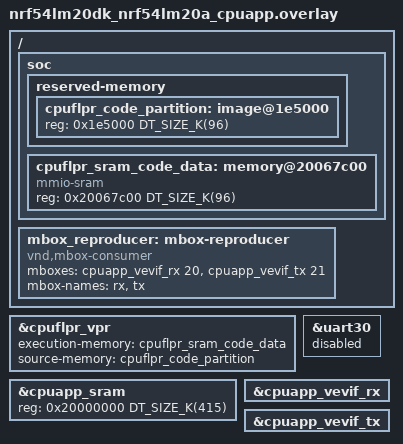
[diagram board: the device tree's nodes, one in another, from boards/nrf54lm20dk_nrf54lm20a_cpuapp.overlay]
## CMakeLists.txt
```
#
# Copyright (c) 2026 Nordic Semiconductor ASA
#
# SPDX-License-Identifier: LicenseRef-Nordic-5-Clause
#

cmake_minimum_required(VERSION 3.20.0)
find_package(Zephyr REQUIRED HINTS $ENV{ZEPHYR_BASE})
project(vevif_back_to_back)

target_sources(app PRIVATE src/main.c)
```

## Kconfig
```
#
# Copyright (c) 2026 Nordic Semiconductor ASA
#
# SPDX-License-Identifier: LicenseRef-Nordic-5-Clause
#

menu "VEVIF Back-To-Back Reproducer"

choice REPRO_MODE
	prompt "Back-to-back scenario"
	default REPRO_MODE_TASK_BURST

config REPRO_MODE_TASK_BURST
	bool "Host sends two back-to-back notifications"

config REPRO_MODE_REVERSE_BURST
	bool "Remote sends two back-to-back notifications after host kick"

endchoice

config REPRO_ITERATIONS
	int "Number of iterations"
	range 1 100000
	default 200

config REPRO_START_DELAY_MS
	int "Producer startup delay in milliseconds"
	range 0 60000
	default 2000

config REPRO_ITERATION_GAP_MS
	int "Delay between back-to-back pairs in milliseconds"
	range 0 1000
	default 1

config REPRO_OVERALL_TIMEOUT_MS
	int "Consumer timeout in milliseconds"
	range 1 60000
	default 10000

endmenu

source "Kconfig.zephyr"
```

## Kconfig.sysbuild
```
#
# Copyright (c) 2026 Nordic Semiconductor ASA
#
# SPDX-License-Identifier: LicenseRef-Nordic-5-Clause
#

source "share/sysbuild/Kconfig"

config REMOTE_BOARD
	string "Remote board"
	default "nrf54lm20dk/nrf54lm20a/cpuflpr" if "$(BOARD_TARGET_STRING)" = "NRF54LM20DK_NRF54LM20A_CPUAPP"
	default "nrf54lm20dk/nrf54lm20b/cpuflpr" if "$(BOARD_TARGET_STRING)" = "NRF54LM20DK_NRF54LM20B_CPUAPP"
	default "nrf54h20dk/nrf54h20/cpuflpr" if "$(BOARD_TARGET_STRING)" = "NRF54H20DK_NRF54H20_CPUAPP"
```

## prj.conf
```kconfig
CONFIG_MBOX=y
CONFIG_CONSOLE=y
CONFIG_PRINTK=y
CONFIG_SERIAL=y
CONFIG_MAIN_STACK_SIZE=2048
```

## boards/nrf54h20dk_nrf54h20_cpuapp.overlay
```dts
/*
 * Copyright 2026 Nordic Semiconductor ASA
 * SPDX-License-Identifier: LicenseRef-Nordic-5-Clause
 */

/ {
	mbox_reproducer: mbox-reproducer {
		compatible = "vnd,mbox-consumer";
		mboxes = <&cpuapp_bellboard 14>, <&cpuflpr_vevif 16>;
		mbox-names = "rx", "tx";
	};
};

&cpuflpr_vpr {
	status = "okay";
};

&cpuapp_bellboard {
	status = "okay";
};

&cpuflpr_vevif {
	status = "okay";
};
```

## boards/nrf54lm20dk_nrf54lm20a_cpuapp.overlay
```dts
/*
 * Copyright 2026 Nordic Semiconductor ASA
 * SPDX-License-Identifier: LicenseRef-Nordic-5-Clause
 */

/ {
	soc {
		reserved-memory {
			#address-cells = <1>;
			#size-cells = <1>;

			cpuflpr_code_partition: image@1e5000 {
				reg = <0x1e5000 DT_SIZE_K(96)>;
			};
		};

		cpuflpr_sram_code_data: memory@20067c00 {
			compatible = "mmio-sram";
			reg = <0x20067c00 DT_SIZE_K(96)>;
			#address-cells = <1>;
			#size-cells = <1>;
			ranges = <0x0 0x20067c00 DT_SIZE_K(96)>;
		};
	};

	mbox_reproducer: mbox-reproducer {
		compatible = "vnd,mbox-consumer";
		mboxes = <&cpuapp_vevif_rx 20>, <&cpuapp_vevif_tx 21>;
		mbox-names = "rx", "tx";
	};
};

&cpuflpr_vpr {
	status = "okay";
	execution-memory = <&cpuflpr_sram_code_data>;
	source-memory = <&cpuflpr_code_partition>;
};

&cpuapp_sram {
	reg = <0x20000000 DT_SIZE_K(415)>;
	ranges = <0x0 0x20000000 DT_SIZE_K(415)>;
};

&uart30 {
	status = "reserved";
};

&cpuapp_vevif_rx {
	status = "okay";
};

&cpuapp_vevif_tx {
	status = "okay";
};
```

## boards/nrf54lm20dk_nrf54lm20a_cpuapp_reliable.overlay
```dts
/*
 * Copyright 2026 Nordic Semiconductor ASA
 * SPDX-License-Identifier: LicenseRef-Nordic-5-Clause
 */

/ {
	reserved-memory {
		#address-cells = <1>;
		#size-cells = <1>;
		ranges;

		vevif_reliable_shm: memory@2007fc00 {
			compatible = "zephyr,memory-region", "mmio-sram";
			reg = <0x2007fc00 0x100>;
			zephyr,memory-region = "MBOX_VEVIF_RELIABLE_SHM";
		};
	};

	vevif_reliable: vevif-reliable {
		compatible = "nordic,nrf-vevif-reliable";
		#mbox-cells = <1>;
		memory-region = <&vevif_reliable_shm>;
		mboxes = <&cpuapp_vevif_rx 20>, <&cpuapp_vevif_tx 21>;
		mbox-names = "rx", "tx";
		nordic,local-id = <0>;
	};
};

&mbox_reproducer {
	mboxes = <&vevif_reliable 1>, <&vevif_reliable 0>;
};
```

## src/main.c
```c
/*
 * Copyright 2026 Nordic Semiconductor ASA
 *
 * SPDX-License-Identifier: LicenseRef-Nordic-5-Clause
 */

#include <errno.h>
#include <zephyr/drivers/mbox.h>
#include <zephyr/kernel.h>
#include <zephyr/sys/atomic.h>
#include <zephyr/sys/printk.h>

#if !DT_NODE_EXISTS(DT_PATH(mbox_reproducer))
#error "Missing /mbox-reproducer devicetree node"
#endif

#if !defined(REPRO_SIDE_REMOTE)
#define REPRO_SIDE_REMOTE 0
#endif

#define REPRO_NODE DT_PATH(mbox_reproducer)
#define RX_MBOX_NODE DT_PHANDLE_BY_IDX(REPRO_NODE, mboxes, 0)
#define TX_MBOX_NODE DT_PHANDLE_BY_IDX(REPRO_NODE, mboxes, 1)

#if DT_NODE_HAS_COMPAT(RX_MBOX_NODE, nordic_nrf_vevif_event_rx)
#define RX_KIND "vevif-event-rx"
#elif DT_NODE_HAS_COMPAT(RX_MBOX_NODE, nordic_nrf_vevif_task_rx)
#define RX_KIND "vevif-task-rx"
#elif DT_NODE_HAS_COMPAT(RX_MBOX_NODE, nordic_nrf_bellboard_rx)
#define RX_KIND "bellboard-rx"
#else
#define RX_KIND "unknown-rx"
#endif

#if DT_NODE_HAS_COMPAT(TX_MBOX_NODE, nordic_nrf_vevif_event_tx)
#define TX_KIND "vevif-event-tx"
#elif DT_NODE_HAS_COMPAT(TX_MBOX_NODE, nordic_nrf_vevif_task_tx)
#define TX_KIND "vevif-task-tx"
#elif DT_NODE_HAS_COMPAT(TX_MBOX_NODE, nordic_nrf_bellboard_tx)
#define TX_KIND "bellboard-tx"
#else
#define TX_KIND "unknown-tx"
#endif

#if defined(CONFIG_REPRO_MODE_TASK_BURST) == defined(CONFIG_REPRO_MODE_REVERSE_BURST)
#error "Select exactly one reproducer mode"
#endif

#if defined(CONFIG_REPRO_MODE_TASK_BURST)
#define REPRO_MODE_NAME "task-burst"
#define REPRO_CONSUMER_REMOTE 1
#else
#define REPRO_MODE_NAME "reverse-burst"
#define REPRO_CONSUMER_REMOTE 0
#endif

#if REPRO_SIDE_REMOTE == REPRO_CONSUMER_REMOTE
#define REPRO_IS_CONSUMER 1
#else
#define REPRO_IS_CONSUMER 0
#endif

static const struct mbox_dt_spec rx_channel = MBOX_DT_SPEC_GET(REPRO_NODE, rx);
static const struct mbox_dt_spec tx_channel = MBOX_DT_SPEC_GET(REPRO_NODE, tx);

static atomic_t callback_count;

static bool wait_for_at_least(atomic_t *value, int expected, uint32_t timeout_ms)
{
	int64_t deadline = k_uptime_get() + timeout_ms;

	do {
		if (atomic_get(value) >= expected) {
			return true;
		}

		k_sleep(K_MSEC(1));
	} while (k_uptime_get() < deadline);

	return atomic_get(value) >= expected;
}

static int send_notification_pair(void)
{
	int ret;

	ret = mbox_send_dt(&tx_channel, NULL);
	if (ret < 0) {
		return ret;
	}

	return mbox_send_dt(&tx_channel, NULL);
}

static void rx_callback(const struct device *dev, mbox_channel_id_t channel_id,
			void *user_data, struct mbox_msg *data)
{
	ARG_UNUSED(dev);
	ARG_UNUSED(channel_id);
	ARG_UNUSED(user_data);
	ARG_UNUSED(data);

	atomic_inc(&callback_count);
}

static void print_banner(const char *role)
{
	printk("REPRO START board=%s role=%s mode=%s tx=%s rx=%s tx_ch=%u rx_ch=%u iterations=%d\n",
	       CONFIG_BOARD_TARGET, role, REPRO_MODE_NAME, TX_KIND, RX_KIND, tx_channel.channel_id,
	       rx_channel.channel_id, CONFIG_REPRO_ITERATIONS);
}


static int setup_consumer(void)
{
	int ret;

	if (!mbox_is_ready_dt(&rx_channel)) {
		printk("RESULT FAIL reason=rx-not-ready mode=%s role=consumer rx=%s\n",
		       REPRO_MODE_NAME, RX_KIND);
		return -ENODEV;
	}

	ret = mbox_register_callback_dt(&rx_channel, rx_callback, NULL);
	if (ret < 0) {
		printk("RESULT FAIL reason=register-callback mode=%s role=consumer ret=%d rx=%s\n",
		       REPRO_MODE_NAME, ret, RX_KIND);
		return ret;
	}

	ret = mbox_set_enabled_dt(&rx_channel, true);
	if (ret < 0) {
		printk("RESULT FAIL reason=set-enabled mode=%s role=consumer ret=%d rx=%s\n",
		       REPRO_MODE_NAME, ret, RX_KIND);
		return ret;
	}

	return 0;
}

static int setup_producer(void)
{
	if (!mbox_is_ready_dt(&tx_channel)) {
		printk("RESULT FAIL reason=tx-not-ready mode=%s role=producer tx=%s\n",
		       REPRO_MODE_NAME, TX_KIND);
		return -ENODEV;
	}

	return 0;
}

static void run_consumer(void)
{
	int ret;
	int expected = CONFIG_REPRO_ITERATIONS * 2;
	bool done;

	print_banner("consumer");

	ret = setup_consumer();
	if (ret < 0) {
		return;
	}

	done = wait_for_at_least(&callback_count, expected, CONFIG_REPRO_OVERALL_TIMEOUT_MS);
	printk("RESULT %s mode=%s role=consumer tx=%s rx=%s expected=%d observed=%d timeout_ms=%d\n",
	       done ? "PASS" : "FAIL", REPRO_MODE_NAME, TX_KIND, RX_KIND, expected,
	       atomic_get(&callback_count), CONFIG_REPRO_OVERALL_TIMEOUT_MS);

	while (true) {
		k_sleep(K_FOREVER);
	}
}

static void run_producer(void)
{
	int ret;

	print_banner("producer");

	ret = setup_producer();
	if (ret < 0) {
		return;
	}

	k_sleep(K_MSEC(CONFIG_REPRO_START_DELAY_MS));

	for (int iteration = 0; iteration < CONFIG_REPRO_ITERATIONS; iteration++) {
		ret = send_notification_pair();
		if (ret < 0) {
			printk("RESULT FAIL reason=send-error mode=%s role=producer iter=%d ret=%d tx=%s\n",
			       REPRO_MODE_NAME, iteration, ret, TX_KIND);
			return;
		}

		if (CONFIG_REPRO_ITERATION_GAP_MS > 0) {
			k_sleep(K_MSEC(CONFIG_REPRO_ITERATION_GAP_MS));
		}
	}

	printk("REPRO PRODUCER DONE mode=%s tx=%s iterations=%d\n",
		REPRO_MODE_NAME, TX_KIND, CONFIG_REPRO_ITERATIONS);

	while (true) {
		k_sleep(K_FOREVER);
	}
}

int main(void)
{
#if REPRO_IS_CONSUMER
	run_consumer();
#else
	run_producer();
#endif

	return 0;
}
```
